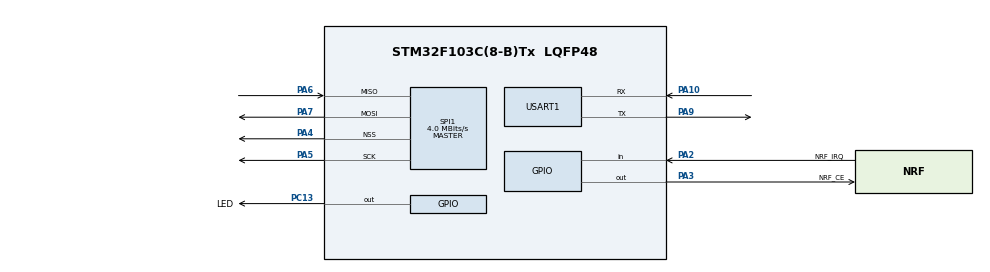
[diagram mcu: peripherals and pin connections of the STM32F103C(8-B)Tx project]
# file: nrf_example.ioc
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Mcu.Family=STM32F1
Mcu.Name=STM32F103C(8-B)Tx
Mcu.Package=LQFP48
NVIC.PriorityGroup=NVIC_PRIORITYGROUP_4
PA10.Mode=Asynchronous
PA10.Signal=USART1_RX
PA13.Mode=Serial_Wire
PA13.Signal=SYS_JTMS-SWDIO
PA14.Mode=Serial_Wire
PA14.Signal=SYS_JTCK-SWCLK
PA2.GPIO_Label=NRF_IRQ
PA2.GPIO_PuPd=GPIO_PULLUP
PA2.Signal=GPIO_Input
PA3.GPIO_Label=NRF_CE
PA3.Signal=GPIO_Output
PA4.Mode=NSS_Signal_Hard_Output
PA4.Signal=SPI1_NSS
PA5.Mode=Full_Duplex_Master
PA5.Signal=SPI1_SCK
PA6.Mode=Full_Duplex_Master
PA6.Signal=SPI1_MISO
PA7.Mode=Full_Duplex_Master
PA7.Signal=SPI1_MOSI
PA9.Mode=Asynchronous
PA9.Signal=USART1_TX
PC13-TAMPER-RTC.GPIO_Label=LED
PC13-TAMPER-RTC.GPIO_ModeDefaultOutputPP=GPIO_MODE_OUTPUT_OD
PC13-TAMPER-RTC.Signal=GPIO_Output
ProjectManager.HeapSize=0x00
ProjectManager.StackSize=0x400
ProjectManager.TargetToolchain=Makefile
RCC.APB1Freq_Value=8000000
RCC.APB2Freq_Value=8000000
SPI1.CalculateBaudRate=4.0 MBits/s
SPI1.Direction=SPI_DIRECTION_2LINES
SPI1.Mode=SPI_MODE_MASTER
SPI1.VirtualNSS=VM_NSSHARD
SPI1.VirtualType=VM_MASTER
USART1.VirtualMode=VM_ASYNC
board=nrf_example

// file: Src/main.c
/**
 ******************************************************************************
 * @file           : main.c
 * @brief          : Main program body
 ******************************************************************************
 ** This notice applies to any and all portions of this file
 * that are not between comment pairs USER CODE BEGIN and
 * USER CODE END. Other portions of this file, whether
 * inserted by the user or by software development tools
 * are owned by their respective copyright owners.
 *
 * COPYRIGHT(c) 2018 STMicroelectronics
 *
 * Redistribution and use in source and binary forms, with or without
 *modification, are permitted provided that the following conditions are met:
 *   1. Redistributions of source code must retain the above copyright notice,
 *      this list of conditions and the following disclaimer.
 *   2. Redistributions in binary form must reproduce the above copyright
 *notice, this list of conditions and the following disclaimer in the
 *documentation and/or other materials provided with the distribution.
 *   3. Neither the name of STMicroelectronics nor the names of its contributors
 *      may be used to endorse or promote products derived from this software
 *      without specific prior written permission.
 *
 * THIS SOFTWARE IS PROVIDED BY THE COPYRIGHT HOLDERS AND CONTRIBUTORS "AS IS"
 * AND ANY EXPRESS OR IMPLIED WARRANTIES, INCLUDING, BUT NOT LIMITED TO, THE
 * IMPLIED WARRANTIES OF MERCHANTABILITY AND FITNESS FOR A PARTICULAR PURPOSE
 *ARE DISCLAIMED. IN NO EVENT SHALL THE COPYRIGHT HOLDER OR CONTRIBUTORS BE
 *LIABLE FOR ANY DIRECT, INDIRECT, INCIDENTAL, SPECIAL, EXEMPLARY, OR
 *CONSEQUENTIAL DAMAGES (INCLUDING, BUT NOT LIMITED TO, PROCUREMENT OF
 *SUBSTITUTE GOODS OR SERVICES; LOSS OF USE, DATA, OR PROFITS; OR BUSINESS
 *INTERRUPTION) HOWEVER CAUSED AND ON ANY THEORY OF LIABILITY, WHETHER IN
 *CONTRACT, STRICT LIABILITY, OR TORT (INCLUDING NEGLIGENCE OR OTHERWISE)
 *ARISING IN ANY WAY OUT OF THE USE OF THIS SOFTWARE, EVEN IF ADVISED OF THE
 *POSSIBILITY OF SUCH DAMAGE.
 *
 ******************************************************************************
 */
#include "main.h"
#include "stm32f1xx_hal.h"

/* USER CODE BEGIN Includes */
#include "example.h"
/* USER CODE END Includes */

SPI_HandleTypeDef hspi1;
UART_HandleTypeDef huart1;
/* USER CODE BEGIN PV */
/* Private variables ---------------------------------------------------------*/

/* USER CODE END PV */

void SystemClock_Config(void);
static void MX_GPIO_Init(void);
static void MX_USART1_UART_Init(void);
static void MX_SPI1_Init(void);

/* USER CODE BEGIN PFP */
/* Private function prototypes -----------------------------------------------*/

/* USER CODE END PFP */

int main(void) {

    /* MCU
     * Configuration----------------------------------------------------------*/

    /* Reset of all peripherals, Initializes the Flash interface and the
     * Systick. */
    HAL_Init();

    /* Configure the system clock */
    SystemClock_Config();

    /* Initialize all configured peripherals */
    MX_GPIO_Init();
		MX_USART1_UART_Init();
    MX_SPI1_Init();
    /* USER CODE BEGIN 2 */
		example();
    /* USER CODE END 2 */

    /* Infinite loop */
    while (1)
		{

    }
}

void SystemClock_Config(void) {

    RCC_OscInitTypeDef RCC_OscInitStruct;
    RCC_ClkInitTypeDef RCC_ClkInitStruct;

    /**Initializes the CPU, AHB and APB busses clocks
     */
    RCC_OscInitStruct.OscillatorType      = RCC_OSCILLATORTYPE_HSI;
    RCC_OscInitStruct.HSIState            = RCC_HSI_ON;
    RCC_OscInitStruct.HSICalibrationValue = 16;
    RCC_OscInitStruct.PLL.PLLState        = RCC_PLL_NONE;
    if (HAL_RCC_OscConfig(&RCC_OscInitStruct) != HAL_OK) {
        _Error_Handler(__FILE__, __LINE__);
    }

    /**Initializes the CPU, AHB and APB busses clocks
     */
    RCC_ClkInitStruct.ClockType = RCC_CLOCKTYPE_HCLK | RCC_CLOCKTYPE_SYSCLK |
                                  RCC_CLOCKTYPE_PCLK1 | RCC_CLOCKTYPE_PCLK2;
    RCC_ClkInitStruct.SYSCLKSource   = RCC_SYSCLKSOURCE_HSI;
    RCC_ClkInitStruct.AHBCLKDivider  = RCC_SYSCLK_DIV1;
    RCC_ClkInitStruct.APB1CLKDivider = RCC_HCLK_DIV1;
    RCC_ClkInitStruct.APB2CLKDivider = RCC_HCLK_DIV1;

    if (HAL_RCC_ClockConfig(&RCC_ClkInitStruct, FLASH_LATENCY_0) != HAL_OK) {
        _Error_Handler(__FILE__, __LINE__);
    }

    /**Configure the Systick interrupt time
     */
    HAL_SYSTICK_Config(HAL_RCC_GetHCLKFreq() / 1000);

    /**Configure the Systick
     */
    HAL_SYSTICK_CLKSourceConfig(SYSTICK_CLKSOURCE_HCLK);

    /* SysTick_IRQn interrupt configuration */
    HAL_NVIC_SetPriority(SysTick_IRQn, 0, 0);
}

/* SPI1 init function */
static void MX_SPI1_Init(void) {

    /* SPI1 parameter configuration*/
    hspi1.Instance               = SPI1;
    hspi1.Init.Mode              = SPI_MODE_MASTER;
    hspi1.Init.Direction         = SPI_DIRECTION_2LINES;
    hspi1.Init.DataSize          = SPI_DATASIZE_8BIT;
    hspi1.Init.CLKPolarity       = SPI_POLARITY_LOW;
    hspi1.Init.CLKPhase          = SPI_PHASE_1EDGE;
    hspi1.Init.NSS               = SPI_NSS_HARD_OUTPUT;
    hspi1.Init.BaudRatePrescaler = SPI_BAUDRATEPRESCALER_2;
    hspi1.Init.FirstBit          = SPI_FIRSTBIT_MSB;
    hspi1.Init.TIMode            = SPI_TIMODE_DISABLE;
    hspi1.Init.CRCCalculation    = SPI_CRCCALCULATION_DISABLE;
    hspi1.Init.CRCPolynomial     = 10;
    if (HAL_SPI_Init(&hspi1) != HAL_OK) { _Error_Handler(__FILE__, __LINE__); }
}
/* USART1 init function */
static void MX_USART1_UART_Init(void)
{

  huart1.Instance = USART1;
  huart1.Init.BaudRate = 115200;
  huart1.Init.WordLength = UART_WORDLENGTH_8B;
  huart1.Init.StopBits = UART_STOPBITS_1;
  huart1.Init.Parity = UART_PARITY_NONE;
  huart1.Init.Mode = UART_MODE_TX_RX;
  huart1.Init.HwFlowCtl = UART_HWCONTROL_NONE;
  huart1.Init.OverSampling = UART_OVERSAMPLING_16;
  if (HAL_UART_Init(&huart1) != HAL_OK)
  {
    _Error_Handler(__FILE__, __LINE__);
  }

}

/** Configure pins as
 * Analog
 * Input
 * Output
 * EVENT_OUT
 * EXTI
 */
static void MX_GPIO_Init(void) {

    GPIO_InitTypeDef GPIO_InitStruct;

    /* GPIO Ports Clock Enable */
    __HAL_RCC_GPIOC_CLK_ENABLE();
    __HAL_RCC_GPIOA_CLK_ENABLE();
	  __HAL_RCC_GPIOB_CLK_ENABLE();

    /*Configure GPIO pin Output Level */
    HAL_GPIO_WritePin(LED_GPIO_Port, LED_Pin, GPIO_PIN_SET);

    /*Configure GPIO pin Output Level */
    HAL_GPIO_WritePin(NRF_CE_GPIO_Port, NRF_CE_Pin, GPIO_PIN_RESET);

    /*Configure GPIO pin : LED_Pin */
    GPIO_InitStruct.Pin   = LED_Pin;
    GPIO_InitStruct.Mode  = GPIO_MODE_OUTPUT_OD;
    GPIO_InitStruct.Speed = GPIO_SPEED_FREQ_LOW;
    HAL_GPIO_Init(LED_GPIO_Port, &GPIO_InitStruct);

    /*Configure GPIO pin : NRF_IRQ_Pin */
    GPIO_InitStruct.Pin  = NRF_IRQ_Pin;
    GPIO_InitStruct.Mode = GPIO_MODE_INPUT;
    GPIO_InitStruct.Pull = GPIO_PULLUP;
    HAL_GPIO_Init(NRF_IRQ_GPIO_Port, &GPIO_InitStruct);

    /*Configure GPIO pin : NRF_CE_Pin */
    GPIO_InitStruct.Pin   = NRF_CE_Pin;
    GPIO_InitStruct.Mode  = GPIO_MODE_OUTPUT_PP;
    GPIO_InitStruct.Speed = GPIO_SPEED_FREQ_LOW;
    HAL_GPIO_Init(NRF_CE_GPIO_Port, &GPIO_InitStruct);
}

void _Error_Handler(char* file, int line) {
    /* USER CODE BEGIN Error_Handler_Debug */
    /* User can add his own implementation to report the HAL error return state
     */
    while (1) {}
    /* USER CODE END Error_Handler_Debug */
}

#ifdef USE_FULL_ASSERT
/**
 * @brief  Reports the name of the source file and the source line number
 *         where the assert_param error has occurred.
 * @param  file: pointer to the source file name
 * @param  line: assert_param error line source number
 * @retval None
 */
void assert_failed(uint8_t* file, uint32_t line) {
    /* USER CODE BEGIN 6 */
    /* User can add his own implementation to report the file name and line
       number, tex: printf("Wrong parameters value: file %s on line %d\r\n",
       file, line) */
    /* USER CODE END 6 */
}
#endif /* USE_FULL_ASSERT */

/************************ (C) COPYRIGHT STMicroelectronics *****END OF FILE****/
